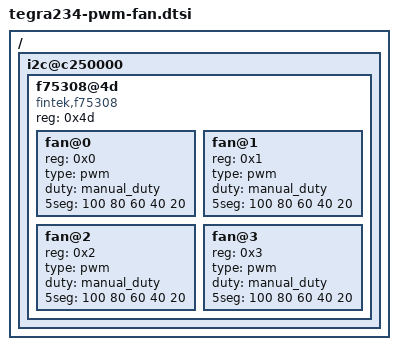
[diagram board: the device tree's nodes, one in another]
/*
 * Copyright (c) 2021-2023, NVIDIA CORPORATION.  All rights reserved.
 *
 * This program is free software; you can redistribute it and/or modify it
 * under the terms and conditions of the GNU General Public License,
 * version 2, as published by the Free Software Foundation.
 *
 * This program is distributed in the hope it will be useful, but WITHOUT
 * ANY WARRANTY; without even the implied warranty of MERCHANTABILITY or
 * FITNESS FOR A PARTICULAR PURPOSE.  See the GNU General Public License for
 * more details.
 *
 * You should have received a copy of the GNU General Public License
 * along with this program.  If not, see <http://www.gnu.org/licenses/>.
 */

/ {
	i2c@c250000 {
		f75308@4d {
			compatible = "fintek,f75308";
			reg = <0x4d>;
			#address-cells = <1>;
			#size-cells = <0>;

			fan@0 {
				reg = <0x0>;
				type = "pwm";
				duty = "manual_duty";
				5seg = <100 80 60 40 20>;
			};

			fan@1 {
				reg = <0x1>;
				type = "pwm";
				duty = "manual_duty";
				5seg = <100 80 60 40 20>;
			};

			fan@2 {
				reg = <0x2>;
				type = "pwm";
				duty = "manual_duty";
				5seg = <100 80 60 40 20>;
			};

			fan@3 {
				reg = <0x3>;
				type = "pwm";
				duty = "manual_duty";
				5seg = <100 80 60 40 20>;
			};
		};
	};
};
